# STM32WB07 register map
File version: 0.4
CPU: CM0+ r0p0, little endian, MPU, no FPU, 2 interrupt priority bits
Registers are 32-bit, read-write, reset 0x0 unless marked. A register's access mark holds for its fields unless they carry their own. Offsets are from the block's base; [hi:lo] are bit positions; 'fields as' and 'values as' point back to an identical list.

## RCC
Base 0x48400000
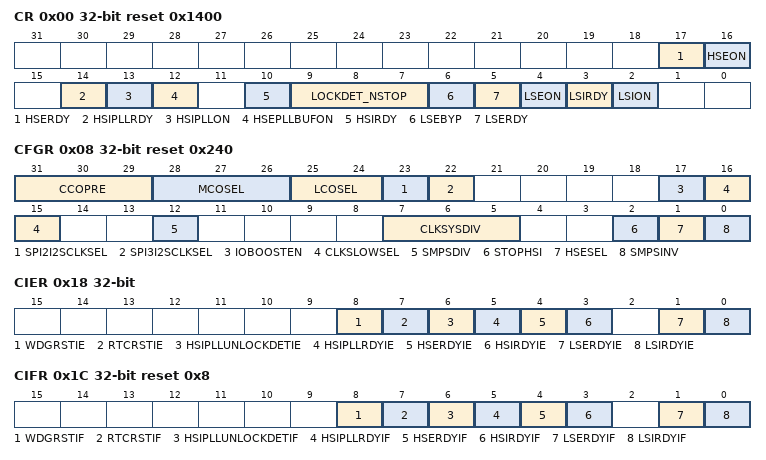
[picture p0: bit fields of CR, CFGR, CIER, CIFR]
0x00 CR reset 0x1400
  [17] HSERDY ro — External High Speed Clock ready flag. Set by hardware to indicate that HSE oscillator is stable.
    0=HSE oscillator not ready; 1=HSE oscillator ready
  [16] HSEON — External High Speed Clock enable. Set and reset by software. in low power mode, HSE is turned off.
    0=HSE oscillator OFF; 1=HSE oscillator ON
  [14] HSIPLLRDY ro — Internal High Speed Clock PLL ready flag.
    0=PLL is unlocked; 1=PLL is locked
  [13] HSIPLLON — Internal High Speed Clock PLL enable
    0=PLL is OFF; 1=PLL is ON
  [12] HSEPLLBUFON — External High Speed Clock Buffer for PLL RF2G4 enable. Set and reset by software.
    0=HSE PLL Buffer OFF; 1=HSE PLL Buffer ON
  [10] HSIRDY ro — Internal High Speed clock ready flag. Set by hardware to indicate that internal RC 64MHz oscillator is stable. This bit is activated only if the RC is enabled by HSION (it is not activated if the RC is enabled by an IP request).
    0=internal RC 64 MHz oscillator not ready; 1=internal RC 64 MHz oscillator ready
  [9:7] LOCKDET_NSTOP — Lock detector Nstop value When start_stop signal is high; a counter is incremented every 16 MHz clock cycle. When the counter reaches (NSTOP+1) x 64 value, the lock_det signal is set high indicating that the PLL is locked. As soon as the start_stop signal is low the counter is reset to 0.
  [6] LSEBYP — External Low Speed Clock bypass. Set and reset by software. Reset source only for this field: PORESETn
    0=LSE oscillator bypass OFF; 1=LSE oscillator bypass ON
  [5] LSERDY ro — External Low Speed Clock ready flag. Set by hardware to indicate that LSE oscillator is stable.
    0=LSE oscillator not ready; 1=LSE oscillator ready
  [4] LSEON — External Low Speed Clock enable. Set and reset by software. Reset source only for this field: PORESETn
    0=LSE oscillator OFF; 1=LSE oscillator ON
  [3] LSIRDY ro — Internal Low Speed oscillator Ready Set and reset by hardware to indicate when the Low Speed Internal RC oscillator is stable. Reset source only for this field: PORESETn
    0=LSI RC oscillator not ready; 1=LSI RC oscillator ready
  [2] LSION — Internal Low Speed oscillator enable Set and reset by software. Reset source only for this field: PORESETn
    0=LSI RC oscillator OFF; 1=LSI RC oscillator ON
0x08 CFGR reset 0x240
  [31:29] CCOPRE — Configurable Clock Output Prescaler. Set and reset by software. Glitches propagation if CCOPRE is modified after CCO output is enabled. Others: not used
    0=CCO clock is divided by 1; 1=CCO clock is divided by 2; 2=CCO clock is divided by 4; 3=CCO clock is divided by 8; 4=CCO clock is divided by 16
  [28:26] MCOSEL — Main Configurable Clock Output Selection. Set and reset by software. Glitches propagation possible.
    0=MCO output disabled, no clock on MCO; 1=system clock selected; 2=na; 3=internal RC 64 MHz (HSI) oscillator clock selected; 4=external oscillator (HSE) clock selected; 5=internal RC 64 MHz (HSI) oscillator divided by 2048 and used as slow clock selected; 6=SMPS clock selected; 7=AUX ADC ANA clock selected
  [25:24] LCOSEL — Low speed Configurable Clock Output Selection. Set and reset by software. Glitches propagation possible. Reset source only for this field: PORESETn
    0=LCO output disabled, no clock on LCO; 1=internal 32 KHz (LSI_LPMU) oscillator clock selected; 2=internal 32 KHz (LSI) oscillator clock selected; 3=external 32 KHz (LSE) oscillator clock selected
  [23] SPI2I2SCLKSEL — Selection of I2S clock: 1x:64MHz peripheral clock
  [22] SPI3I2SCLKSEL — Selection of I2S1 clock: 1x:64MHz peripheral clock
    0=16MHz peripheral clock (default); 1=32MHz peripheral clock
  [17] IOBOOSTEN — IO BOOSTER enable Set and reset by software.
    0=does not enable IO BOOSTER; 1=enable IO BOOSTER
  [16:15] CLKSLOWSEL — slow clock source selection Set by software to select the clock source. This is no glitch free mechanism Reset source only for this field: PORESETn
    0=LSILMPU oscillator clock (default); 1=LSE oscillator clock used as slow clock; 2=LSI oscillator clock used as slow clock; 3=HSI_64M divided by 2048 used as slow clock
  [12] SMPSDIV — SMPS clock prescaling factor to generate 4MHz or 8MHz
    0=div 2 when ANADIV=2 or 4 (default ); 1=div 4 when ANADIV=1 or 2
  [7:5] CLKSYSDIV — CLKSYSDIV: system clock divided factor from HSI_64M.
  [2] STOPHSI — Stop HSI clock source request
    0=HSI is enabled (default); 1=disable HSI is requested
  [1] HSESEL — Clock source selection request:
    0=HSI clock source is requested (default); 1=HSE clock source is requested
  [0] SMPSINV — bit to control inversion of the SMPS clock
    0=SMPS clock not inverted (default value); 1=SMPS clock inverted (for debug)
0x18 CIER
  [8] WDGRSTIE — WDGRSTIE: Watchdog reset end Interrupt Enable. Set and reset by software to enable/disable interrupt caused by the watchdog reset end.
    0=interrupt disabled; 1=interrupt enabled
  [7] RTCRSTIE — RTCRSTIE: RTC reset end Interrupt Enable. Set and reset by software to enable/disable interrupt caused by the RTC reset end.
    0=HSI PLL unlock detection interrupt disabled; 1=HSI PLL unlock detection interrupt enabled
  [6] HSIPLLUNLOCKDETIE — HSIPLLUNLOCKDETIE: HSI PLL unlock detection Interrupt Enable. Set and reset by software to enable/disable interrupt caused by the HSI 64MHz PLL unlock.
    values as RTCRSTIE
  [5] HSIPLLRDYIE — HSI PLL Ready Interrupt Enable. Set and reset by software to enable/disable interrupt caused by the HSI 64MHz PLL locked on HSE.
    0=HSI PLL ready interrupt disabled; 1=HSI PLL ready interrupt enabled
  [4] HSERDYIE — HSE Ready Interrupt Enable Set and reset by software to enable/disable interrupt caused by the external HSE oscillator stabilization.
    0=HSE ready interrupt disabled; 1=HSE ready interrupt enabled
  [3] HSIRDYIE — HSI Ready Interrupt Enable. Set and reset by software to enable/disable interrupt caused by the internal RC 64MHz oscillator stabilization.
    0=HSI ready interrupt disabled; 1=HSI ready interrupt enabled
  [1] LSERDYIE — LSE Ready Interrupt Enable. Set and reset by software to enable/disable interrupt caused by the external 32 kHz oscillator stabilization.
    0=LSE ready interrupt disabled; 1=LSE ready interrupt enabled
  [0] LSIRDYIE — LSI Ready Interrupt Enable. Set and reset by software to enable/disable interrupt caused by internal RC 32 kHz oscillator stabilization.
    0=LSI ready interrupt disabled; 1=LSI ready interrupt enabled
0x1C CIFR reset 0x8
  [8] WDGRSTIF — WDG reset end Interrupt Flag. Raised when reset is released on 32kHz clock
  [7] RTCRSTIF — RTC reset end Interrupt Flag. Raised when reset is released on 32kHz clock
  [6] HSIPLLUNLOCKDETIF — HSIPLLUNLOCKDETIF: HSI PLL unlock detection Interrupt Flag.
  [5] HSIPLLRDYIF — HSI PLL Ready Interrupt Flag. Set by hardware when HSI PLL 64MHz becomes stable.
    0=No clock ready interrupt caused by the HSI PLL64 MHz oscillator; 1=Clock ready interrupt caused by the HSI PLL64 MHz oscillator
  [4] HSERDYIF — HSE Ready Interrupt Flag. Set by hardware when HSE becomes stable.
    0=No clock ready interrupt caused by the HSE oscillator; 1=Clock ready interrupt caused by the HSE oscillator
  [3] HSIRDYIF — HSI Ready Interrupt Flag. Set by hardware when HSI becomes stable.
    0=No clock ready interrupt caused by the HSI oscillator; 1=Clock ready interrupt caused by the HSI oscillator
  [1] LSERDYIF — LSE Ready Interrupt Flag. Set by hardware when LSE clock becomes stable.
    0=No clock ready interrupt caused by the LSE oscillator; 1=Clock ready interrupt caused by the LSE oscillator
  [0] LSIRDYIF — LSI Ready Interrupt flag Set by hardware when LSI clock becomes stable.
    0=No clock ready interrupt caused by the internal RC 32 KHz oscillator; 1=Clock ready interrupt caused by the internal RC 32 kHz oscillator
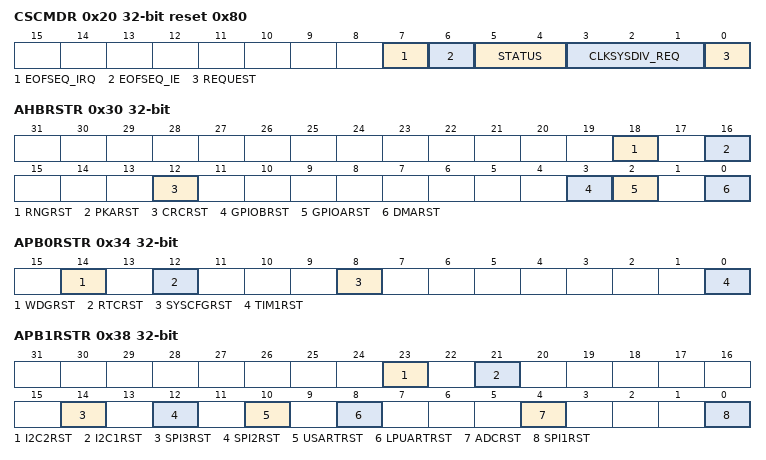
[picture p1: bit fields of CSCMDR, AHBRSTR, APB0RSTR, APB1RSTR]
0x20 CSCMDR reset 0x80
  [7] EOFSEQ_IRQ — End of Sequence flag Set by hardware when clock system swtich is ended
    0=No end of sequence event occured; 1=End of sequece event occured
  [6] EOFSEQ_IE — End of sequence Interrupt Enable. Set and reset by software to enable/disable interrupt caused by the clock system switch.
    0=End of sequence interrupt disabled; 1=End of sequence interrupt enabled
  [5:4] STATUS ro — Status of clock switch sequence
    0=IDLE no switch requested; 1=ONGOING clock frequency switch is ongoing; 2=DONE clock frequency switch done
  [3:1] CLKSYSDIV_REQ — system clock dividing factor from HSI_64M requested Note: behavior depends on BLEEN in APB2ENR register
    0=div 1 (sys clock 64M); 1=div 2 (sys clock 32M); 2=div 4 (sys clock 16M); 3=div 8 (sys clock 8M); 4=div 16 (sys clock 4M); 5=div 32 (sys clock 2M); 6=div 64 (sys clock 1M)
  [0] REQUEST — Request for system clock switching Cleared by hardware when system clock frequency switch is done
    0=To cancel an ongiong request - still possible until IRQ assertion; 1=To update the system clock frequency
0x30 AHBRSTR
  [18] RNGRST — RNG reset Set and reset by software.
    0=does not reset; 1=resets
  [16] PKARST — PKA reset Set and reset by software.
    0=does not reset; 1=resets
  [12] CRCRST — CRC reset Set and reset by software.
    0=does not reset CRC; 1=resets CRC
  [3] GPIOBRST — GPIOB reset Set and reset by software.
    0=does not reset; 1=resets
  [2] GPIOARST — GPIOA reset Set and reset by software.
    0=does not reset; 1=resets
  [0] DMARST — DMA and DMAMUX reset Set and reset by software.
    0=does not reset DMA; 1=resets DMA
0x34 APB0RSTR
  [all] fields
    0=does not reset; 1=resets
  [14] WDGRST — WATCHDOG reset Set and reset by software.
  [12] RTCRST — RTC reset Set and reset by software.
  [8] SYSCFGRST — SYSTEM CONFIG reset Set and reset by software.
  [0] TIM1RST — TIM1: Advanced Timer reset Set and reset by software.
0x38 APB1RSTR
  [23] I2C2RST — 2C2 reset.
  [21] I2C1RST — I2C1 reset Set and reset by software.
    0=does not reset; 1=resets
  [14] SPI3RST — SPI3 reset Set and reset by software.
    0=does not reset; 1=resets
  [12] SPI2RST — SPI2 reset.
  [10] USARTRST — USART reset Set and reset by software.
    0=does not reset; 1=resets
  [8] LPUARTRST — LPUART reset Set and reset by software.
    0=does not reset; 1=resets
  [4] ADCRST — ADC reset.
  [0] SPI1RST — SPI1 reset
0x40 APB2RSTR
  [0] MRBLERST — MR_BLE (Bluetooth radio) reset.
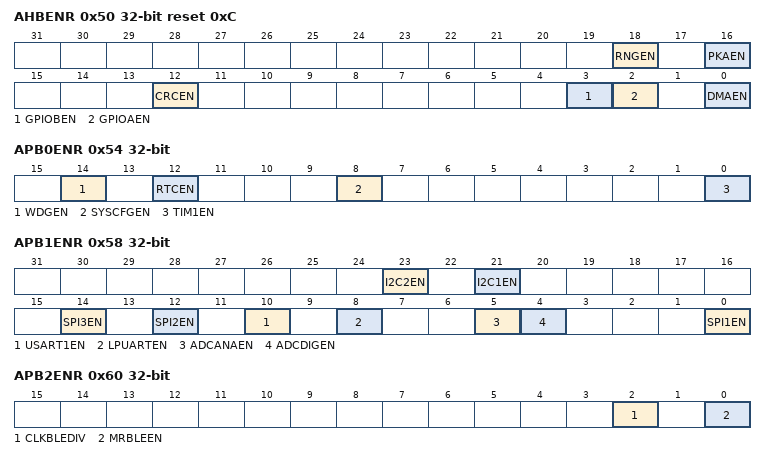
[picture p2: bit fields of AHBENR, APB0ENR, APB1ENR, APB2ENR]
0x50 AHBENR reset 0xC
  [18] RNGEN — RNG clock enable Set and enable by software.
    0=does not enable; 1=enable
  [16] PKAEN — PKA clock enable Set and enable by software.
    0=does not enable; 1=enable
  [12] CRCEN — CRC enable Set and enable by software.
    0=does not enable; 1=enable
  [3] GPIOBEN — GPIOB enable. It must be enabled by default
  [2] GPIOAEN — GPIOA enable. It must be enabled by default
  [0] DMAEN — DMA and DMAMUX enable Set and enable by software.
    0=does not enable; 1=enable
0x54 APB0ENR
  [all] fields
    0=does not enable; 1=enable
  [14] WDGEN — Watchdog clock enable. Set and enable by software.
  [12] RTCEN — RTC clock enable Set and enable by software. Reset source only for this field: PORESETn
  [8] SYSCFGEN — SYSTEM CONFIG enable Set and enable by software.
  [0] TIM1EN — TIM1 enable
0x58 APB1ENR
  [23] I2C2EN — I2C2 enable.
  [21] I2C1EN — I2C1 clock enable Set and enable by software.
    0=does not enable; 1=enable
  [14] SPI3EN — SPI3 clock enable Set and enable by software.
    0=does not enable; 1=enable
  [12] SPI2EN — SPI2 enable
  [10] USART1EN — USART clock enable Set and enable by software.
    0=does not enable; 1=enable
  [8] LPUARTEN — LPUART clock enable Set and enable by software.
    0=does not enable; 1=enable
  [5] ADCANAEN — ADC clock enable for the analog part of the ADC block.
  [4] ADCDIGEN — ADC clock enable for digital part of the ADC block.
    0=does not enable; 1=enable
  [0] SPI1EN — SPI1 enable.
    0=does not enable; 1=enable
0x60 APB2ENR
  [2] CLKBLEDIV — MR_BLE clock frequency selection when RCC_APB2ENR.MRBLEEN=1
    0=32MHz; 1=16MHz
  [0] MRBLEEN — MR_BLE enable
    0=MR_BLE IP is clock gated; 1=MR_BLE IP is clocked
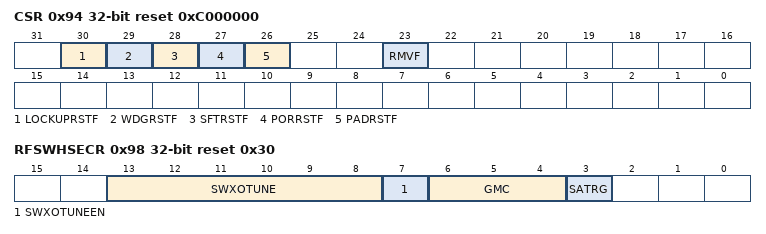
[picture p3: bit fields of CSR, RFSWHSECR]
0x94 CSR reset 0xC000000
  [30] LOCKUPRSTF ro — LOCK UP reset flag from CM0 Reset by software by writing the RMVF bit. Set by hardware from unrecoverable exception CPU. It reset V12i domain, FLASH controller and peripherals.
    0=No lockup reset occurred; 1=lockup reset occurred
  [29] WDGRSTF ro — Watchdog reset flag Reset by software by writing the RMVF bit. Set by hardware when a watchdog reset from V33 domain occurs.
    0=No watchdog reset occurred; 1=Watchdog reset occurred
  [28] SFTRSTF ro — Software reset flag Reset by software by writing the RMVF bit. Set by hardware when a software reset occurs.
    0=No software reset occurred; 1=Software reset occurred
  [27] PORRSTF ro — POWER reset flag Reset by software by writing the RMVF bit. Set by hardware when a power reset occurs from LPMURESET block.
    0=No POWER reset occurred; 1=POWER reset occurred
  [26] PADRSTF ro — SYSTEM reset flag Reset by software by writing the RMVF bit. Set by hardware when a reset from pad occurs.
    0=No reset from pad occurred; 1=Reset from pad occurred
  [23] RMVF wo — Remove reset flag Set by software to clear the value of the reset flags. It auto clears by HW after clearing reason flags
    0=Nothing done; 1=Reset the value of the reset flags
0x98 RFSWHSECR reset 0x30
  [13:8] SWXOTUNE — RF-HSE capacitor bank tuning value by SW Set by software
  [7] SWXOTUNEEN — RF-HSE capacitor bank tuning by SW enable Set by software
  [6:4] GMC — High Speed External XO current control Set by software.
    0=max 0.0 001: max 0.57 mA/V; 2=max 0.78 mA/V; 3=max 1.13 mA/V (Default); 4=max 0.61 mA/V; 5=max 1.65 mA/V; 6=max 2.12 mA/V; 7=max 2.84 mA/V
  [3] SATRG — Sense Amplifier threshold Set by software.
    0=the bias current is confronted to a reference current with a ratio of half; 1=the bias current is confronted to a reference current with a ratio of 3/4
0x9C RFHSECR ro
  [5:0] XOTUNE — RF-HSE capacitor bank tuning Set by option byte loading soon after Power On Reset.

## Notices in the file
Copyright (c) 2024 STMicroelectronics.
SPDX-License-Identifier: Apache-2.0
Licensed under the Apache License, Version 2.0 (the "License");
you may not use this file except in compliance with the License.
You may obtain a copy of the License at
http://www.apache.org/licenses/LICENSE-2.0
Unless required by applicable law or agreed to in writing, software
distributed under the License is distributed on an "AS IS" BASIS,
WITHOUT WARRANTIES OR CONDITIONS OF ANY KIND, either express or implied.
See the License for the specific language governing permissions and
limitations under the License.
